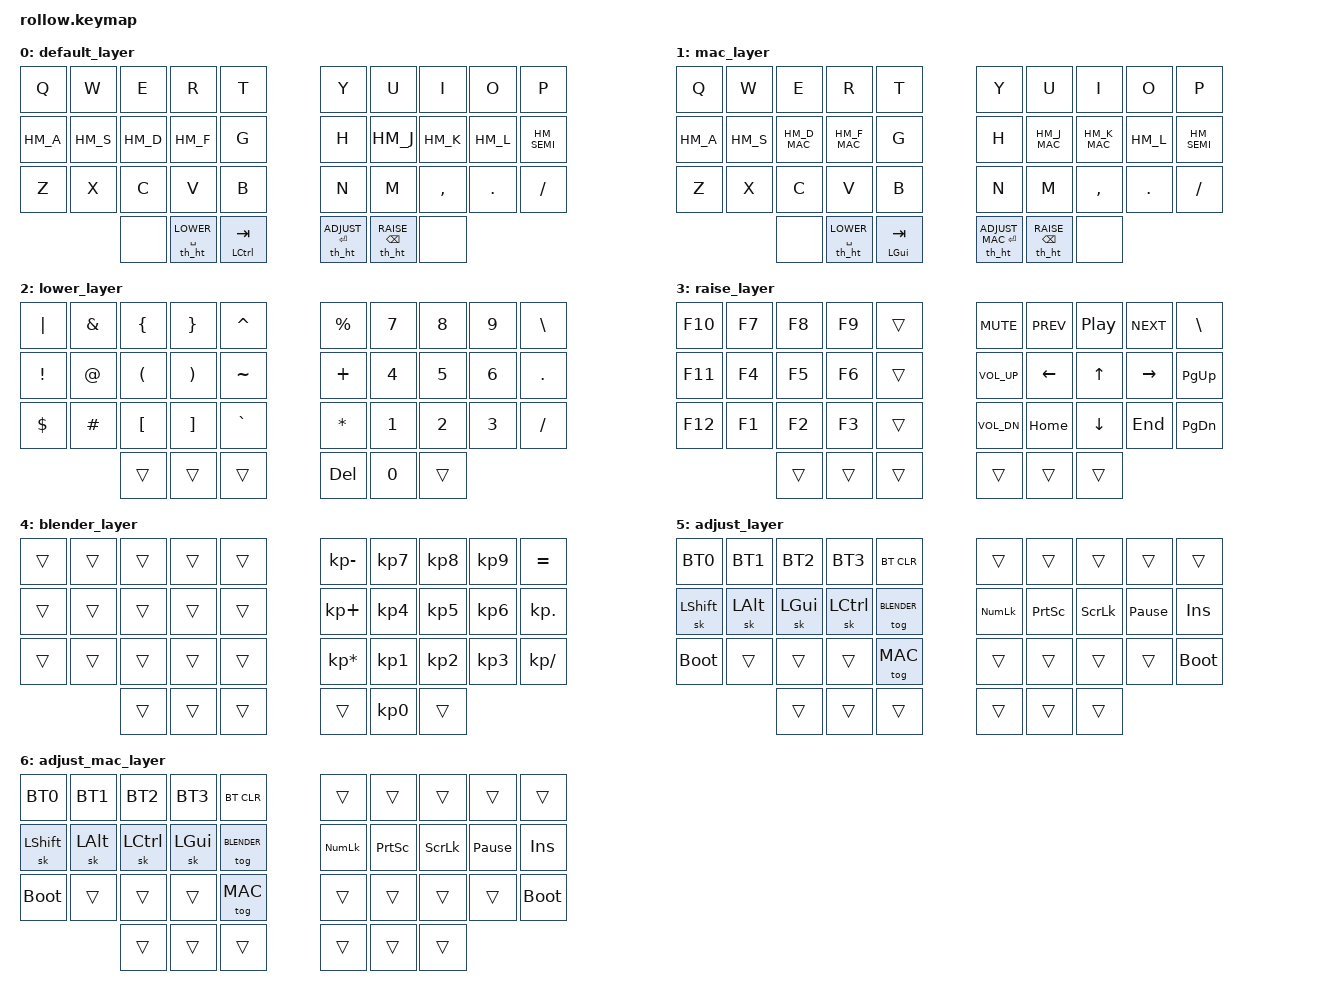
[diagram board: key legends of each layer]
#include <behaviors.dtsi>
#include <dt-bindings/zmk/keys.h>
#include <dt-bindings/zmk/bt.h>

#include "definitions.dtsi"
#include "homerow.dtsi"
#include "combos.dtsi"
// #include "unicode.dtsi"
// #include "tapdances.dtsi"
// TODO SQT, CG_TOGG

&caps_word {
        continue-list = <UNDERSCORE MINUS>;
};
/ {
        chosen {
                zmk,matrix_transform = &five_column_transform;
        };

        keymap {
                compatible = "zmk,keymap";

                default_layer {
                        bindings = <
                        &kp Q &kp W &kp E &kp R &kp T   &kp Y &kp U  &kp I     &kp O   &kp P
                        HM_A  HM_S  HM_D  HM_F  &kp G   &kp H HM_J   HM_K      HM_L    HM_SEMI
                        &kp Z &kp X &kp C &kp V &kp B   &kp N &kp M  &kp COMMA &kp DOT &kp FSLH
                        &none &th_ht LOWER SPACE &hm_sl LCTL TAB   &th_ht ADJUST RET &th_ht RAISE BSPC &none
                        >;
                        sensor-bindings = <&inc_dec_kp C_VOL_UP C_VOL_DN &inc_dec_kp RIGHT LEFT>;
                };

                mac_layer {
                        bindings = <
                        &kp Q &kp W &kp E &kp R &kp T   &kp Y &kp U  &kp I     &kp O   &kp P
                        HM_A  HM_S  HM_D_MAC  HM_F_MAC  &kp G   &kp H HM_J_MAC   HM_K_MAC      HM_L    HM_SEMI
                        &kp Z &kp X &kp C &kp V &kp B   &kp N &kp M  &kp COMMA &kp DOT &kp FSLH
                        &none &th_ht LOWER SPACE &hm_sl LGUI TAB   &th_ht ADJUST_MAC RET &th_ht RAISE BSPC &none
                        >;
                        sensor-bindings = <&inc_dec_kp C_VOL_UP C_VOL_DN &inc_dec_kp RIGHT LEFT>;
                };

                lower_layer {
                        bindings = <
                        &kp PIPE &kp AMPS &kp LBRC &kp RBRC &kp CARET   &kp PRCNT &kp N7 &kp N8 &kp N9 &kp BSLH
                        &kp EXCL &kp AT   &kp LPAR &kp RPAR &kp TILDE   &kp PLUS  &kp N4 &kp N5 &kp N6 &kp DOT
                        &kp DLLR &kp HASH &kp LBKT &kp RBKT &kp GRAVE   &kp STAR  &kp N1 &kp N2 &kp N3 &kp FSLH
                                                 &trans &trans &trans   &kp DEL &kp N0 &trans
                        >;
                        sensor-bindings = <&inc_dec_kp DOWN UP &inc_dec_kp DOWN UP>;
                };

                raise_layer {
                        bindings = <
                        &kp F10 &kp F7 &kp F8 &kp F9 &trans     &kp C_MUTE   &kp C_PREV &kp C_PP &kp C_NEXT &kp BSLH
                        &kp F11 &kp F4 &kp F5 &kp F6 &trans     &kp C_VOL_UP &kp LEFT   &kp UP   &kp RIGHT  &kp PG_UP
                        &kp F12 &kp F1 &kp F2 &kp F3 &trans     &kp C_VOL_DN &kp HOME   &kp DOWN &kp END    &kp PG_DN
                                       &trans &trans &trans     &trans &trans &trans
                        >;
                        sensor-bindings = <&inc_dec_kp DOWN UP &inc_dec_kp DOWN UP>;
                };

                blender_layer {
                        bindings = <
                        &trans &trans &trans &trans &trans      &kp KP_MINUS    &kp KP_N7 &kp KP_N8 &kp KP_N9 &kp EQUAL
                        &trans &trans &trans &trans &trans      &kp KP_PLUS     &kp KP_N4 &kp KP_N5 &kp KP_N6 &kp KP_DOT
                        &trans &trans &trans &trans &trans      &kp KP_ASTERISK &kp KP_N1 &kp KP_N2 &kp KP_N3 &kp KP_SLASH
                                      &trans &trans &trans      &trans &kp KP_N0 &trans
                        >;
                        sensor-bindings = <&inc_dec_kp DOWN UP &inc_dec_kp DOWN UP>;
                };

                adjust_layer {
                        bindings = <
                        BT0       BT1      BT2       BT3      &bt BT_CLR      &trans &trans &trans &trans &trans
                        &sk LSHFT &sk LALT &sk LGUI  &sk LCTL &tog BLENDER    &kp KP_NLCK &kp PSCRN &kp SLCK &kp PAUSE_BREAK &kp INS
                        &bootloader &trans   &trans    &trans   &tog MAC        &trans &trans &trans &trans &bootloader
                                                      &trans &trans &trans    &trans &trans &trans
                        >;
                };

                adjust_mac_layer {
                        bindings = <
                        BT0       BT1      BT2       BT3      &bt BT_CLR      &trans &trans &trans &trans &trans
                        &sk LSHFT &sk LALT &sk LCTL  &sk LGUI &tog BLENDER    &kp KP_NLCK &kp PSCRN &kp SLCK &kp PAUSE_BREAK &kp INS
                        &bootloader &trans   &trans    &trans   &tog MAC        &trans &trans &trans &trans &bootloader
                                                      &trans &trans &trans    &trans &trans &trans
                        >;
                };
        };
};
